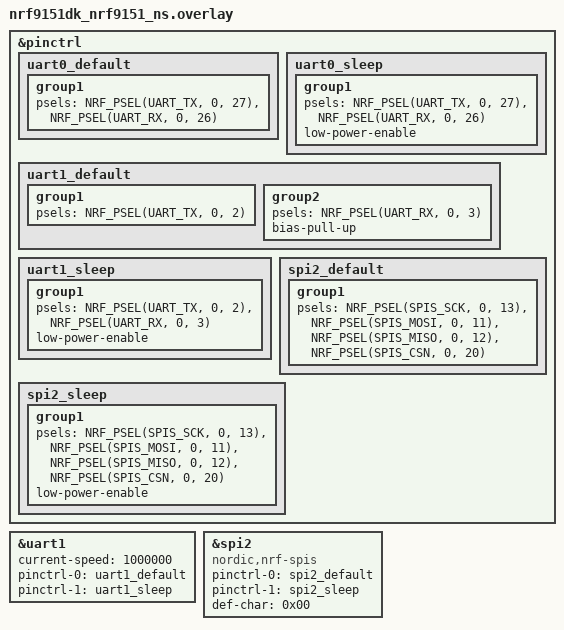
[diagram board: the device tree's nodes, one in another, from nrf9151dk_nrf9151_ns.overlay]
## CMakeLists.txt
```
#
# Copyright (c) 2025 Nordic Semiconductor ASA
#
# SPDX-License-Identifier: LicenseRef-Nordic-5-Clause
#

cmake_minimum_required(VERSION 3.20.0)

find_package(Zephyr REQUIRED HINTS $ENV{ZEPHYR_BASE})
project(hello_dect)

target_sources(app PRIVATE
    src/main.c
    src/uart.c
    src/sync.c
    src/dect_net.c
)

if(NOT CONFIG_DECT_RELAY_PT AND NOT CONFIG_DECT_RELAY_FT)
    target_sources(app PRIVATE src/spi.c)
endif()
```

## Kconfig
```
#
# Copyright (c) 2025 Nordic Semiconductor ASA
#
# SPDX-License-Identifier: LicenseRef-Nordic-5-Clause
#

source "Kconfig.zephyr"

menu "Hello DECT sample configuration"

config HELLO_DECT_MAC_DEMO_INTERVAL
	int "Demo message interval in seconds"
	default 30
	help
	  Interval in seconds for sending demo messages when connected.

config DECT_TRANSMITTER_ID
	int "DECT NR+ Transmitter ID"
	default 38
	help
	  DECT NR+ Transmitter ID (long rd id). Range 0..65535

config DECT_RELAY_PT
	bool "DECT NR+ Relay PT"
	default n
	help
	  Enable DECT NR+ Relay PT functionality. If enabled, the device will act as a relay for DECT NR+ messages.

config DECT_RELAY_FT
	bool "DECT NR+ Relay FT"
	default n
	help
	  Enable DECT NR+ Relay FT functionality. If enabled, the device will act as a relay for DECT NR+ messages.

config DECT_EDGE_PT
	bool "DECT NR+ PT Edge"
	default n
	help
	  Enable DECT NR+ Edge PT functionality.

config SPI
	depends on !DECT_RELAY_PT && !DECT_RELAY_FT


module = HELLO_DECT_MAC
module-str = Log level for Hello DECT sample application
source "${ZEPHYR_BASE}/subsys/logging/Kconfig.template.log_config"



endmenu
```

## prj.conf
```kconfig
# Modem library
CONFIG_NRF_MODEM_LIB=y
CONFIG_NRF_MODEM_LINK_BINARY_DECT=y
CONFIG_NRF_MODEM_LIB_ON_FAULT_APPLICATION_SPECIFIC=y

# DECT NR+ driver configuration
CONFIG_DECT=y
CONFIG_DECT_MDM=y
CONFIG_DECT_MDM_DRIVER_NRF=y

# DECT NR+ network ID for both devices
CONFIG_DECT_DEFAULT_NW_ID=0x12345678

# Networking
CONFIG_NETWORKING=y
CONFIG_NET_NATIVE=y
CONFIG_NET_IPV4=n
CONFIG_NET_IPV6=y
CONFIG_NRF_MODEM_LIB_SHMEM_TX_SIZE=16384

# Network management
CONFIG_NET_MGMT=y
CONFIG_NET_MGMT_EVENT=y
CONFIG_NET_MGMT_EVENT_INFO=y
CONFIG_NET_MGMT_EVENT_INFO_DEFAULT_DATA_SIZE=208

# DECT NR+ L2 and connection manager
CONFIG_NET_L2_DECT_MGMT=y
CONFIG_NET_CONNECTION_MANAGER=y
CONFIG_NET_CONNECTION_MANAGER_MONITOR_STACK_SIZE=2048
CONFIG_NET_L2_DECT_CONN_MGR_AUTO_CONNECT=n
CONFIG_NET_L2_DECT_CONN_MGR_CONNECTION_PERSISTENCE=y

# Basic networking components
CONFIG_NET_SOCKETS=y
CONFIG_NET_SOCKETS_PACKET=y
CONFIG_NET_SOCKETS_OFFLOAD=n
CONFIG_POSIX_API=y
CONFIG_NET_IF_MAX_IPV6_COUNT=2
CONFIG_NET_INTERFACE_NAME=y

# Network buffers
CONFIG_NET_BUF=y
CONFIG_NET_BUF_DATA_SIZE=1280
CONFIG_NET_PKT_RX_COUNT=8
CONFIG_NET_BUF_RX_COUNT=8
CONFIG_NET_PKT_TX_COUNT=4
CONFIG_NET_BUF_TX_COUNT=4

# IPv6 neighbor tables, ND itself disabled in net iface
CONFIG_NET_IPV6_NBR_CACHE=y
CONFIG_NET_IPV6_ND=y

# Disable antenna config (not supported by DECT modem)
CONFIG_MODEM_ANTENNA=n
CONFIG_MODEM_ANTENNA_AT_COEX0=""

# Basic kernel and system settings
CONFIG_MAIN_STACK_SIZE=8192
CONFIG_SYSTEM_WORKQUEUE_STACK_SIZE=4096

# DECT NR+ specific settings
CONFIG_DECT_TRANSMITTER_ID=9876
CONFIG_NET_MGMT_EVENT_STACK_SIZE=2048
CONFIG_NET_MGMT_EVENT_QUEUE_SIZE=10
CONFIG_NET_MGMT_EVENT_QUEUE_TIMEOUT=5000

# Enable DK library for LED/button support
CONFIG_DK_LIBRARY=y

# Settings storage
CONFIG_FLASH=y
CONFIG_FLASH_MAP=y
CONFIG_MPU_ALLOW_FLASH_WRITE=y
CONFIG_NVS=y
CONFIG_SETTINGS=y
CONFIG_SETTINGS_NVS=y

# Additional network socket configurations
CONFIG_NET_CONTEXT_SNDTIMEO=y
CONFIG_NET_CONTEXT_RCVTIMEO=y
CONFIG_NET_RX_STACK_SIZE=4096

# Hostname configuration
CONFIG_NET_HOSTNAME_ENABLE=y
CONFIG_NET_HOSTNAME="dect-nr+-device"
CONFIG_NET_HOSTNAME_DYNAMIC=y
CONFIG_NET_HOSTNAME_UNIQUE=n

# Need bigger stack for mDNS
CONFIG_NET_SOCKETS_SERVICE_STACK_SIZE=4096
CONFIG_NRF_MODEM_LIB_SHMEM_RX_SIZE=8192
# Enable logging
CONFIG_LOG=y
CONFIG_NET_LOG=y
CONFIG_PRINTK=y

# Debugging options
CONFIG_ASSERT=y
CONFIG_ASSERT_VERBOSE=y

# Halt application, e.g. on assertion failure
CONFIG_RESET_ON_FATAL_ERROR=n

# SPI
CONFIG_SPI=y
CONFIG_SPI_SLAVE=y

CONFIG_TFM_LOG_LEVEL_SILENCE=y

# UART (image data shares UART0/VCOM0 with log output)
CONFIG_SERIAL=y
CONFIG_UART_ASYNC_API=y

# Use deferred logging so log output does not interleave with binary data
CONFIG_LOG_MODE_DEFERRED=y
```

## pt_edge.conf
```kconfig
CONFIG_DECT_EDGE_PT=y
CONFIG_SPI=y
CONFIG_SPI_SLAVE=y
```

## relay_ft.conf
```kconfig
CONFIG_DECT_RELAY_FT=y
CONFIG_SPI=n
CONFIG_SPI_SLAVE=n
```

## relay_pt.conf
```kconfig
CONFIG_DECT_RELAY_PT=y
CONFIG_RING_BUFFER=y
CONFIG_RING_BUFFER_LARGE=y
CONFIG_SPI=n
CONFIG_SPI_SLAVE=n
```

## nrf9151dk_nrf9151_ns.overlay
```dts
&pinctrl {

    uart0_default: uart0_default {
        group1 {
            psels = <NRF_PSEL(UART_TX, 0, 27)>,
                    <NRF_PSEL(UART_RX, 0, 26)>;
        };
    };

    uart0_sleep: uart0_sleep {
        group1 {
            psels = <NRF_PSEL(UART_TX, 0, 27)>,
                    <NRF_PSEL(UART_RX, 0, 26)>;
            low-power-enable;
        };
    };

    uart1_default: uart1_default {
    group1 {
        psels = <NRF_PSEL(UART_TX, 0, 2)>;
    };
    group2 {
        psels = <NRF_PSEL(UART_RX, 0, 3)>;
        bias-pull-up;  /* RX needs pull-up, separate group */
    };
    };
    uart1_sleep: uart1_sleep {
        group1 {
            psels = <NRF_PSEL(UART_TX, 0, 2)>,
                    <NRF_PSEL(UART_RX, 0, 3)>;
            low-power-enable;
        };
    };

    spi2_default: spi2_default {
        group1 {
            psels = <NRF_PSEL(SPIS_SCK, 0, 13)>,
                    <NRF_PSEL(SPIS_MOSI, 0, 11)>,
                    <NRF_PSEL(SPIS_MISO, 0, 12)>,
                    <NRF_PSEL(SPIS_CSN, 0, 20)>;
        };
    };

    spi2_sleep: spi2_sleep {
        group1 {
            psels = <NRF_PSEL(SPIS_SCK, 0, 13)>,
                    <NRF_PSEL(SPIS_MOSI, 0, 11)>,
                    <NRF_PSEL(SPIS_MISO, 0, 12)>,
                    <NRF_PSEL(SPIS_CSN, 0, 20)>;
            low-power-enable;
        };
    };

};

&uart1 {
    status = "okay";
    current-speed = <1000000>;
    pinctrl-0 = <&uart1_default>;
    pinctrl-1 = <&uart1_sleep>;
    pinctrl-names = "default", "sleep";
};

&spi2 {
    compatible = "nordic,nrf-spis";
    status = "okay";
    pinctrl-0 = <&spi2_default>;
    pinctrl-1 = <&spi2_sleep>;
    pinctrl-names = "default", "sleep";
    def-char = <0x00>;
};
```

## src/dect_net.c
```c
#include "dect_net.h"

#include <zephyr/kernel.h>
#include <zephyr/logging/log.h>
#include <zephyr/net/net_mgmt.h>
#include <zephyr/net/net_ip.h>
#include <zephyr/posix/arpa/inet.h>

#include <net/dect/dect_net_l2_mgmt.h>
#include <net/dect/dect_net_l2.h>
#include <net/dect/dect_utils.h>

#include "uart.h"   /* ROUTING_MAX_HOPS */

LOG_MODULE_REGISTER(dect_net, LOG_LEVEL_INF);

#define RSSI_CACHE_SIZE ROUTING_MAX_HOPS

static struct net_if   *dect_iface;
static struct in6_addr  mesh_prefix;
static uint32_t         current_long_rd_id;
static uint32_t         best_long_rd_id;
static uint8_t          best_route_cost;

static struct {
    uint32_t long_rd_id;
    int8_t   rssi;
} rssi_cache[RSSI_CACHE_SIZE];

/* ── Internal helpers ── */

static bool create_ipv6_internal(struct in6_addr *addr, uint32_t long_rd_id)
{
    bool ok = dect_utils_lib_net_ipv6_addr_create_from_sink_and_long_rd_id(
        mesh_prefix, DECT_SINK_LONG_RD_ID, long_rd_id, addr);
    if (!ok) LOG_ERR("Failed to create IPv6 address for 0x%08x", long_rd_id);
    return ok;
}

static void create_and_set_device_ipv6(void)
{
    net_addr_pton(AF_INET6, MESH_PREFIX_STR, &mesh_prefix);

    struct in6_addr global_addr;
    if (!create_ipv6_internal(&global_addr, current_long_rd_id)) return;

    net_if_ipv6_addr_add(dect_iface, &global_addr, NET_ADDR_MANUAL, 0);

    char addr_str[NET_IPV6_ADDR_LEN];
    net_addr_ntop(AF_INET6, &global_addr, addr_str, sizeof(addr_str));
    LOG_INF("Adding global IPv6: %s", addr_str);
}

/* ── Public API ── */

void dect_net_init(struct net_if *iface)
{
    dect_iface      = iface;
    best_long_rd_id = 0;
    best_route_cost = 0xFF;
}

void dect_net_write_ft_settings(void)
{
    struct dect_settings s = {0};
    int ret = net_mgmt(NET_REQUEST_DECT_SETTINGS_READ, dect_iface, &s, sizeof(s));
    if (ret) {
        LOG_ERR("Failed to read settings: %d", ret);
        return;
    }

    s.device_type = DECT_DEVICE_TYPE_FT;
#if IS_ENABLED(CONFIG_DECT_RELAY_FT)
    s.identities.transmitter_long_rd_id = DECT_FT_LONG_RD_ID;
#else
    s.identities.transmitter_long_rd_id = DECT_SINK_LONG_RD_ID;
#endif

    // Disable auto-start
    s.auto_start.activate = false;

    s.nw_beacon.channel       = 1657;
    s.nw_beacon.beacon_period = DECT_NW_BEACON_PERIOD_1000MS;
    s.cmd_params.write_scope_bitmap =
        DECT_SETTINGS_WRITE_SCOPE_AUTO_START  |
        DECT_SETTINGS_WRITE_SCOPE_DEVICE_TYPE |
        DECT_SETTINGS_WRITE_SCOPE_IDENTITIES  |
        DECT_SETTINGS_WRITE_SCOPE_NW_BEACON;

    ret = net_mgmt(NET_REQUEST_DECT_SETTINGS_WRITE, dect_iface, &s, sizeof(s));
    if (ret) {
        LOG_ERR("Failed to write settings: %d", ret);
        return;
    }

    current_long_rd_id = s.identities.transmitter_long_rd_id;
    create_and_set_device_ipv6();
    LOG_INF("FT settings written (long_rd_id=0x%08x)", current_long_rd_id);
}

void dect_net_write_pt_settings(void)
{
    struct dect_settings s = {0};
    int ret = net_mgmt(NET_REQUEST_DECT_SETTINGS_READ, dect_iface, &s, sizeof(s));
    if (ret) {
        LOG_ERR("Failed to read settings: %d", ret);
        return; 
    }

    s.device_type = DECT_DEVICE_TYPE_PT;
#if IS_ENABLED(CONFIG_DECT_RELAY_PT)
    s.identities.transmitter_long_rd_id = DECT_PT_LONG_RD_ID;
#else
    s.identities.transmitter_long_rd_id = DECT_EDGE_PT_LONG_RD_ID;
#endif

    // Disable auto-start
    s.auto_start.activate = false;

    s.cmd_params.write_scope_bitmap =
        DECT_SETTINGS_WRITE_SCOPE_AUTO_START    |
        DECT_SETTINGS_WRITE_SCOPE_DEVICE_TYPE   |
        DECT_SETTINGS_WRITE_SCOPE_IDENTITIES;

    ret = net_mgmt(NET_REQUEST_DECT_SETTINGS_WRITE, dect_iface, &s, sizeof(s));
    if (ret) {
        LOG_ERR("Failed to write settings: %d", ret);
        return;
    }

    current_long_rd_id = s.identities.transmitter_long_rd_id;
    create_and_set_device_ipv6();
    LOG_INF("PT settings written (long_rd_id=0x%08x)", current_long_rd_id);
}

void dect_net_start_beacon(void)
{
    struct dect_nw_beacon_start_req_params p = {
        .channel = 1657,
        .additional_ch_count = 0,
    };
    int ret = net_mgmt(NET_REQUEST_DECT_NW_BEACON_START, dect_iface, &p, sizeof(p));
    if (ret) LOG_ERR("Beacon start failed: %d", ret);
}

void dect_net_start_scan(void)
{
    best_long_rd_id = 0;
    best_route_cost = 0xFF;

    struct dect_scan_params p = {
        .band = 1,
        .channel_count = 0,
        .channel_scan_time_ms = 1200,
    };
    int ret = net_mgmt(NET_REQUEST_DECT_SCAN, dect_iface, &p, sizeof(p)); // Callback to NET_EVENT_DECT_SCAN_RESULT and NET_EVENT_DECT_SCAN_DONE
    if (ret) LOG_ERR("Scan start failed: %d", ret);
}

void dect_net_consider_ft(uint32_t long_rd_id, uint8_t route_cost)
{
    if (route_cost < best_route_cost) {
        best_route_cost = route_cost;
        best_long_rd_id = long_rd_id;
        LOG_INF("New best FT: 0x%08x (cost=%d)", best_long_rd_id, best_route_cost);
    }
}

bool dect_net_has_best_ft(void)
{
    return best_long_rd_id != 0;
}

void dect_net_join_best(void)
{
    struct dect_settings s = {0};
    int ret = net_mgmt(NET_REQUEST_DECT_SETTINGS_READ, dect_iface, &s, sizeof(s));
    if (ret) { LOG_ERR("Failed to read settings: %d", ret); return; }

    s.network_join.target_ft_long_rd_id = best_long_rd_id;
    s.cmd_params.write_scope_bitmap |= DECT_SETTINGS_WRITE_SCOPE_NETWORK_JOIN;

    ret = net_mgmt(NET_REQUEST_DECT_SETTINGS_WRITE, dect_iface, &s, sizeof(s));
    if (ret) { LOG_ERR("Failed to write join settings: %d", ret); return; }

    ret = net_mgmt(NET_REQUEST_DECT_NETWORK_JOIN, dect_iface, NULL, 0); // Callback to NET_EVENT_DECT_NETWORK_STATUS->Joined
    if (ret) LOG_ERR("Network join failed: %d", ret);
    else     LOG_INF("Joining FT 0x%08x", best_long_rd_id);
}

uint32_t dect_net_get_current_long_rd_id(void)
{
    return current_long_rd_id;
}

const struct in6_addr *dect_net_get_mesh_prefix(void)
{
    return &mesh_prefix;
}

uint32_t dect_net_get_parent_long_rd_id(void)
{
    struct dect_status_info info = {0};
    int ret = net_mgmt(NET_REQUEST_DECT_STATUS_INFO_GET, dect_iface, &info, sizeof(info));
    if (ret) { LOG_ERR("Failed to get status info: %d", ret); return 0; }
    if (info.parent_count == 0) return 0;
    return info.parent_associations->long_rd_id;
}

bool dect_net_create_ipv6(struct in6_addr *addr, uint32_t long_rd_id)
{
    return create_ipv6_internal(addr, long_rd_id);
}

void dect_net_update_rssi(uint32_t long_rd_id, int8_t rssi)
{
    for (int i = 0; i < RSSI_CACHE_SIZE; i++) {
        if (rssi_cache[i].long_rd_id == long_rd_id || rssi_cache[i].long_rd_id == 0) {
            rssi_cache[i].long_rd_id = long_rd_id;
            rssi_cache[i].rssi       = rssi;
            return;
        }
    }
    /* Cache full - overwrite slot 0 */
    rssi_cache[0].long_rd_id = long_rd_id;
    rssi_cache[0].rssi       = rssi;
}

int8_t dect_net_get_rx_rssi(struct sockaddr_in6 *src_addr)
{
    uint32_t long_rd_id = dect_utils_lib_long_rd_id_from_ipv6_addr(&src_addr->sin6_addr);
    if (long_rd_id == 0) return 0;

    struct dect_neighbor_info_req_params p = { .long_rd_id = long_rd_id };
    int ret = net_mgmt(NET_REQUEST_DECT_NEIGHBOR_INFO, dect_iface, &p, sizeof(p));
    if (ret) LOG_WRN("Neighbor info request failed: %d", ret);

    for (int i = 0; i < RSSI_CACHE_SIZE; i++) {
        if (rssi_cache[i].long_rd_id == long_rd_id) return rssi_cache[i].rssi;
    }
    return 0;
}
```

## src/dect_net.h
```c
#ifndef DECT_NET_H
#define DECT_NET_H

#include <zephyr/net/net_if.h>
#include <zephyr/net/net_ip.h>
#include <zephyr/posix/sys/socket.h>
#include <stdint.h>
#include <stdbool.h>

/* Device identities - single source of truth for the whole project */
#define DECT_EDGE_PT_LONG_RD_ID     0xAAAAAAAAU

//#define DECT_FT_LONG_RD_ID          0xBBBBBBBBU
//#define DECT_PT_LONG_RD_ID          0xCCCCCCCCU

#define DECT_FT_LONG_RD_ID          0xDDDDDDDDU
#define DECT_PT_LONG_RD_ID          0xEEEEEEEEU

#define DECT_SINK_LONG_RD_ID        0x67FFFFFFU
#define MESH_PREFIX_STR           "fd12:3456:789a"

/* Must be called before any other dect_net function */
void dect_net_init(struct net_if *iface);

/* Settings */
void dect_net_write_ft_settings(void);
void dect_net_write_pt_settings(void);

/* Network operations */
void dect_net_start_beacon(void);
void dect_net_start_scan(void);
void dect_net_consider_ft(uint32_t long_rd_id, uint8_t route_cost);
bool dect_net_has_best_ft(void);
void dect_net_join_best(void);

/* Queries */
uint32_t             dect_net_get_current_long_rd_id(void);
const struct in6_addr *dect_net_get_mesh_prefix(void);
uint32_t             dect_net_get_parent_long_rd_id(void);
bool                 dect_net_create_ipv6(struct in6_addr *addr, uint32_t long_rd_id);

/* RSSI - update called from NET_EVENT_DECT_NEIGHBOR_INFO handler */
void   dect_net_update_rssi(uint32_t long_rd_id, int8_t rssi);
int8_t dect_net_get_rx_rssi(struct sockaddr_in6 *src_addr);

#endif /* DECT_NET_H */
```

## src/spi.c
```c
#include <zephyr/kernel.h>
#include <zephyr/device.h>
#include <zephyr/drivers/spi.h>
#include <zephyr/logging/log.h>
#include "spi.h"

LOG_MODULE_REGISTER(spi_slave, LOG_LEVEL_INF);

#define READY_PIN_NODE DT_NODELABEL(gpio0)
#define READY_PIN 6

static const struct device *gpio_dev;

#define SPI_NODE DT_NODELABEL(spi2)
#define TX_BUFFER_SIZE 1024
#define CHUNK_SIZE 4096
#define MAX_IMAGE_SIZE 16384

K_THREAD_STACK_DEFINE(spi_slave_stack, 12288);
static struct k_thread spi_slave_thread_data;
static k_tid_t spi_slave_thread_id;

static uint8_t tx_buffer[TX_BUFFER_SIZE];
static uint8_t rx_buffer[CHUNK_SIZE];
static uint8_t image_buffer[MAX_IMAGE_SIZE];

static size_t total_received = 0;
static size_t image_size = 0;
static bool new_image_available = false;
static bool receiving_image = false;
K_MUTEX_DEFINE(image_mutex);

static struct spi_config spi_cfg = {
    .frequency = 8000000,
    .operation = SPI_OP_MODE_SLAVE |
                 SPI_TRANSFER_MSB |
                 SPI_WORD_SET(8) |
                 SPI_MODE_CPOL |
                 SPI_MODE_CPHA,
    .slave = 0,
    .cs = NULL};

static struct spi_buf tx_buf = {
    .buf = tx_buffer,
    .len = TX_BUFFER_SIZE};

static struct spi_buf_set tx_buf_set = {
    .buffers = &tx_buf,
    .count = 1};

static struct spi_buf rx_buf = {
    .buf = rx_buffer,
    .len = CHUNK_SIZE};

static struct spi_buf_set rx_buf_set = {
    .buffers = &rx_buf,
    .count = 1};

static bool find_jpeg_end(uint8_t *buffer, size_t len, size_t *end_pos)
{
    bool found = false;

    if (len < 2) return false;

    for (size_t i = 0; i < len - 1; i++)
    {
        if (buffer[i] == 0xFF && buffer[i + 1] == 0xD9)
        {
            *end_pos = i + 2;
            found = true;
        }
    }
    return found;
}

int spi_slave_init(void)
{
    const struct device *spi_dev;

    LOG_INF("Initializing SPI slave...");
    spi_dev = DEVICE_DT_GET(SPI_NODE);

    if (spi_dev == NULL)
    {
        LOG_ERR("Device pointer is NULL!");
        return -ENODEV;
    }

    if (!device_is_ready(spi_dev))
    {
        LOG_ERR("SPI device not ready");
        return -ENODEV;
    }
    gpio_dev = DEVICE_DT_GET(READY_PIN_NODE);
    if (!device_is_ready(gpio_dev))
    {
        LOG_ERR("GPIO device not ready");
        return -ENODEV;
    }

    gpio_pin_configure(gpio_dev, READY_PIN, GPIO_OUTPUT_ACTIVE);
    gpio_pin_set(gpio_dev, READY_PIN, 0);  /* Not ready until thread arms */

    LOG_INF("Ready pin (P0.06) initialized");
    LOG_INF("SPI slave initialized: %s", spi_dev->name);
    return 0;
}

void spi_slave_receive_thread(void *p1, void *p2, void *p3)
{
    const struct device *spi_dev;
    int ret;
    size_t eoi_pos;
    uint8_t prev_last_byte = 0;

    ARG_UNUSED(p1);
    ARG_UNUSED(p2);
    ARG_UNUSED(p3);

    LOG_INF("SPI slave thread starting...");

    spi_dev = DEVICE_DT_GET(SPI_NODE);
    if (!device_is_ready(spi_dev))
    {
        LOG_ERR("SPI device not ready");
        return;
    }

    LOG_INF("SPI slave ready, waiting for master...");

    while (1)
    {
        /* If the previous image has not been consumed yet, keep ready LOW and
         * wait here. The SPI thread owns the ready pin - it will raise it once
         * it re-arms spi_transceive. */
        {
            bool pending;
            do {
                k_mutex_lock(&image_mutex, K_FOREVER);
                pending = new_image_available;
                k_mutex_unlock(&image_mutex);
                if (pending) k_sleep(K_MSEC(10));
            } while (pending);
        }

        /* Arm the slave for the next chunk.
         * Signal ready HIGH *before* calling spi_transceive. The Pi requires
         * at least ~100µs of Python/ioctl overhead after seeing HIGH before CS
         * is asserted, which is far longer than the ~5µs spi_transceive needs
         * to arm the SPIS hardware. The race window is negligible in practice. */
        rx_buf.len = CHUNK_SIZE;
        tx_buf.len = TX_BUFFER_SIZE;
        gpio_pin_set(gpio_dev, READY_PIN, 1);
        ret = spi_transceive(spi_dev, &spi_cfg, &tx_buf_set, &rx_buf_set);

        /* Signal LOW immediately - tells Pi "I'm processing, don't send yet".
         * Pi will wait for this LOW then the next HIGH before sending the
         * following chunk. */
        gpio_pin_set(gpio_dev, READY_PIN, 0);

        if (ret < 0)
        {
            LOG_ERR("SPI transceive failed: %d", ret);
            continue;
        }

        size_t bytes_received = rx_buf.len;
        if (bytes_received == 0)
            continue;

        /* Detect start of new image */
        if (rx_buffer[0] == 0xFF && rx_buffer[1] == 0xD8)
        {
            total_received = 0;
            receiving_image = true;
            prev_last_byte = 0;
            memset(image_buffer, 0, MAX_IMAGE_SIZE);
            LOG_INF("New image started");
        }

        if (!receiving_image)
            continue;

        if (total_received + bytes_received > MAX_IMAGE_SIZE)
        {
            LOG_ERR("Image too large, discarding (total=%zu)", total_received);
            receiving_image = false;
            total_received = 0;
            prev_last_byte = 0;
            continue;
        }

        memcpy(image_buffer + total_received, rx_buffer, bytes_received);
        total_received += bytes_received;

        bool eoi_found = false;

        if (prev_last_byte == 0xFF && rx_buffer[0] == 0xD9)
        {
            eoi_pos = 1;
            eoi_found = true;
            LOG_INF("EOI detected across chunk boundary");
        }
        else if (find_jpeg_end(rx_buffer, bytes_received, &eoi_pos))
        {
            eoi_found = true;
        }

        if (eoi_found)
        {
            size_t actual_size = (total_received - bytes_received) + eoi_pos;
            receiving_image = false;
            prev_last_byte = 0;

            k_mutex_lock(&image_mutex, K_FOREVER);
            image_size = actual_size;
            new_image_available = true;
            k_mutex_unlock(&image_mutex);

            LOG_INF("Image complete: %zu bytes", actual_size);
            /* Ready pin stays LOW. Loop restarts and waits at the top until
             * the app consumes the image, then re-arms and raises ready. */
        }
        else
        {
            prev_last_byte = rx_buffer[bytes_received - 1];
            /* Loop back immediately - ready will be raised at the top of the
             * next iteration once spi_transceive is about to be called. */
        }
    }
}

uint8_t *spi_slave_get_image_buffer(void)
{
    return image_buffer;
}

size_t spi_slave_get_image_size(void)
{
    size_t size;
    k_mutex_lock(&image_mutex, K_FOREVER);
    size = image_size;
    k_mutex_unlock(&image_mutex);
    return size;
}

bool spi_slave_is_new_image_available(void)
{
    bool available;
    k_mutex_lock(&image_mutex, K_FOREVER);
    available = new_image_available;
    k_mutex_unlock(&image_mutex);
    return available;
}

void spi_slave_clear_image_flag(void)
{
    k_mutex_lock(&image_mutex, K_FOREVER);
    new_image_available = false;
    k_mutex_unlock(&image_mutex);
    /* Do NOT touch the ready pin here. The SPI thread owns it and will raise
     * it on its next iteration once it has armed spi_transceive. */
    LOG_INF("Image consumed, SPI thread will re-arm");
}

int spi_slave_start_thread(void)
{
    spi_slave_thread_id = k_thread_create(&spi_slave_thread_data,
                                          spi_slave_stack,
                                          K_THREAD_STACK_SIZEOF(spi_slave_stack),
                                          spi_slave_receive_thread,
                                          NULL, NULL, NULL,
                                          7, 0, K_NO_WAIT);

    if (spi_slave_thread_id == NULL)
    {
        LOG_ERR("Failed to create SPI slave thread");
        return -1;
    }

    k_thread_name_set(spi_slave_thread_id, "spi_slave");
    LOG_INF("SPI slave thread started");
    return 0;
}
```

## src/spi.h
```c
#ifndef SPI_SLAVE_H
#define SPI_SLAVE_H

#include <stdint.h>
#include <stddef.h>
#include <stdbool.h>


int spi_slave_init(void);
void spi_slave_receive_thread(void *p1, void *p2, void *p3);
uint8_t* spi_slave_get_image_buffer(void);
size_t spi_slave_get_image_size(void);
bool spi_slave_is_new_image_available(void);
void spi_slave_clear_image_flag(void);
int spi_slave_start_thread(void);

#endif // SPI_SLAVE_H
```

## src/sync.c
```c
#include "sync.h"

#include <zephyr/kernel.h>
#include <zephyr/logging/log.h>
#include <zephyr/net/socket.h>
#include <zephyr/posix/arpa/inet.h>

#include <net/dect/dect_utils.h>

LOG_MODULE_REGISTER(sync, LOG_LEVEL_INF);

#define SYNC_MAGIC_SIGNATURE    0xFEFDU     // The G.O.A.T
#define SYNC_T_SIZE             4
#define SOCKET_SYNC_RX_TIMEOUT_SEC  10
#define SYNC_MAX_RX_RETRIES     5

struct sync_data {
    uint32_t magic_signature;
    uint32_t T[SYNC_T_SIZE];
};

/* Module state set by sync_init() */
static struct net_if   *sync_iface;
static struct in6_addr  sync_mesh_prefix;
static uint32_t         sync_sink_long_rd_id;

static int sync_socket = -1;

/* ── Internal helpers ── */

static bool make_peer_addr(struct sockaddr_in6 *addr, uint32_t long_rd_id)
{
    bool ok = dect_utils_lib_net_ipv6_addr_create_from_sink_and_long_rd_id(
        sync_mesh_prefix, sync_sink_long_rd_id, long_rd_id, &addr->sin6_addr);
    if (!ok) {
        LOG_ERR("Failed to construct IPv6 address for 0x%08x", long_rd_id);
    }
    return ok;
}

static int recv_sync_from_peer(struct sync_data *out, uint32_t *rx_long_rd_id_out,
                               uint32_t *timestamp_out, struct sockaddr_in6 *src_addr_out)
{
    struct sockaddr_in6 src_addr;
    socklen_t addr_len = sizeof(src_addr);
    char addr_str[NET_IPV6_ADDR_LEN];

    int ret = recvfrom(sync_socket, out, sizeof(*out), 0,
                       (struct sockaddr *)&src_addr, &addr_len);
    if (ret < 0) return -errno;

    *timestamp_out = k_uptime_get_32();

    if (out->magic_signature != SYNC_MAGIC_SIGNATURE) {
        LOG_WRN("SYNC magic mismatch (got 0x%08x)", out->magic_signature);
        return -EBADMSG;
    }

    net_addr_ntop(AF_INET6, &src_addr.sin6_addr, addr_str, sizeof(addr_str));
    *rx_long_rd_id_out = dect_utils_lib_long_rd_id_from_ipv6_addr(&src_addr.sin6_addr);
    LOG_INF("SYNC RX: %d bytes from %s (0x%08x)", ret, addr_str, *rx_long_rd_id_out);

    if (src_addr_out) *src_addr_out = src_addr;
    return 0;
}

/* ── Public API ── */

void sync_init(struct net_if *iface, const struct in6_addr *mesh_prefix,
               uint32_t sink_long_rd_id)
{
    sync_iface          = iface;
    sync_mesh_prefix    = *mesh_prefix;
    sync_sink_long_rd_id = sink_long_rd_id;
}

int sync_open_socket(void)
{
    sync_socket = socket(AF_INET6, SOCK_DGRAM, IPPROTO_UDP);
    if (sync_socket < 0) {
        LOG_ERR("Failed to create SYNC socket: %d", errno);
        sync_socket = -1;
        return -errno;
    }

    struct timeval timeout = { .tv_sec = SOCKET_SYNC_RX_TIMEOUT_SEC };
    int dect_iface_idx = net_if_get_by_iface(sync_iface);
    int reuse = 1;

    setsockopt(sync_socket, SOL_SOCKET, SO_RCVTIMEO, &timeout, sizeof(timeout));
    setsockopt(sync_socket, SOL_SOCKET, SO_BINDTODEVICE,
               &dect_iface_idx, sizeof(dect_iface_idx));
    setsockopt(sync_socket, SOL_SOCKET, SO_REUSEADDR, &reuse, sizeof(reuse));

    struct sockaddr_in6 rx_addr = {
        .sin6_family = AF_INET6,
        .sin6_port   = htons(SYNC_PORT),
        .sin6_addr   = in6addr_any,
    };

    int ret = bind(sync_socket, (struct sockaddr *)&rx_addr, sizeof(rx_addr));
    if (ret < 0) {
        LOG_ERR("Failed to bind SYNC socket: %d", errno);
        close(sync_socket);
        sync_socket = -1;
        return -errno;
    }

    LOG_INF("SYNC socket open");
    return 0;
}

void sync_close_socket(void)
{
    if (sync_socket >= 0) {
        close(sync_socket);
        sync_socket = -1;
    }
    LOG_INF("SYNC socket closed");
}

int sync_pt_operation(uint32_t parent_long_rd_id, int32_t *offset_out)
{
    if (sync_socket < 0) {
        LOG_WRN("SYNC socket not open");
        return -ENOTCONN;
    }

    struct sockaddr_in6 dst_addr = {
        .sin6_family = AF_INET6,
        .sin6_port   = htons(SYNC_PORT),
    };
    if (!make_peer_addr(&dst_addr, parent_long_rd_id)) {
        return -EINVAL;
    }

    for (int attempt = 0; attempt < SYNC_MAX_RX_RETRIES; attempt++) {
        /* Send T0 on every attempt so FT Relay gets it even if it wasn't ready */
        struct sync_data pkt = {
            .magic_signature = SYNC_MAGIC_SIGNATURE,
        };
        pkt.T[0] = k_uptime_get_32();

        int ret = sendto(sync_socket, &pkt, sizeof(pkt), 0,
                         (struct sockaddr *)&dst_addr, sizeof(dst_addr));
        if (ret < 0) {
            LOG_WRN("Failed to send SYNC packet: %d", errno);
            continue;
        }
        LOG_INF("SYNC T0 sent (attempt %d, T0=%u)", attempt + 1, pkt.T[0]);

        struct sync_data rx;
        uint32_t rx_long_rd_id;
        uint32_t T3;

        ret = recv_sync_from_peer(&rx, &rx_long_rd_id, &T3, NULL);
        if (ret == -EAGAIN) {
            LOG_WRN("SYNC RX timeout, retrying (%d/%d)", attempt + 1, SYNC_MAX_RX_RETRIES);
            continue;
        }
        if (ret < 0) {
            LOG_WRN("SYNC RX error: %d, retrying", ret);
            continue;
        }
        if (rx_long_rd_id != parent_long_rd_id) {
            LOG_WRN("SYNC RX from unexpected peer 0x%08x (want 0x%08x), retrying",
                    rx_long_rd_id, parent_long_rd_id);
            continue;
        }

        int32_t d1 = (int32_t)(rx.T[1] - pkt.T[0]);   /* T1 - T0 */
        int32_t d2 = (int32_t)(T3 - rx.T[2]);          /* T3 - T2 */
        *offset_out = (d1 - d2) / 2;
        LOG_INF("PTP: d1=%d d2=%d offset=%d", d1, d2, *offset_out);
                return 0;
    }

    LOG_WRN("SYNC PT: exhausted retries");
    return -ETIMEDOUT;
}
int sync_ft_operation(uint32_t child_long_rd_id)
{
    if (sync_socket < 0) {
        LOG_WRN("SYNC socket not open");
        return -ENOTCONN;
    }

    for (int attempt = 0; attempt < SYNC_MAX_RX_RETRIES; attempt++) {
        struct sync_data rx;
        uint32_t rx_long_rd_id;
        uint32_t T1;
        struct sockaddr_in6 reply_addr;

        int ret = recv_sync_from_peer(&rx, &rx_long_rd_id, &T1, &reply_addr);
        if (ret == -EAGAIN) {
            LOG_WRN("SYNC RX timeout, retrying (%d/%d)", attempt + 1, SYNC_MAX_RX_RETRIES);
            continue;
        }
        if (ret < 0) {
            LOG_WRN("SYNC RX error: %d, retrying", ret);
            continue;
        }
        if (rx_long_rd_id != child_long_rd_id) {
            LOG_WRN("SYNC RX from unexpected peer 0x%08x (want 0x%08x), retrying",
                    rx_long_rd_id, child_long_rd_id);
            continue;
        }

        reply_addr.sin6_port = htons(SYNC_PORT);

        struct sync_data reply = {
            .magic_signature = SYNC_MAGIC_SIGNATURE,
        };
        reply.T[0] = rx.T[0];
        reply.T[1] = T1;
        reply.T[2] = k_uptime_get_32();

        ret = sendto(sync_socket, &reply, sizeof(reply), 0,
                     (struct sockaddr *)&reply_addr, sizeof(reply_addr));
        if (ret < 0) {
            LOG_WRN("Failed to send SYNC reply: %d", errno);
            return -errno;
        }

        LOG_INF("SYNC reply sent (T0=%u T1=%u T2=%u)", reply.T[0], reply.T[1], reply.T[2]);
        return 0;
    }

    LOG_WRN("SYNC FT: exhausted retries");
    return -ETIMEDOUT;
}
```

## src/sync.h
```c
#ifndef SYNC_H
#define SYNC_H

#include <zephyr/net/net_if.h>
#include <zephyr/net/net_ip.h>
#include <stdint.h>

#define SYNC_PORT 12346

/*
 * sync_init - store the DECT interface, mesh prefix, and sink long RD ID
 * needed to construct IPv6 addresses for SYNC peers.
 *
 * Must be called before sync_open_socket or either operation.
 */
void sync_init(struct net_if *iface, const struct in6_addr *mesh_prefix,
               uint32_t sink_long_rd_id);

/* Open/close the dedicated SYNC UDP socket (driven by IF_UP / IF_DOWN). */
int  sync_open_socket(void);
void sync_close_socket(void);

/*
 * sync_pt_operation - PT side: send T0, receive T1/T2, compute clock offset.
 *
 * @param parent_long_rd_id  Long RD ID of the parent FT to synchronise with.
 * @param offset_out         Receives the computed PT-to-FT clock offset (ms).
 *
 * Returns 0 on success, negative on failure or timeout.
 */
int sync_pt_operation(uint32_t parent_long_rd_id, int32_t *offset_out);

/*
 * sync_ft_operation - FT side: receive T0 from child PT, echo T1/T2 back.
 *
 * @param child_long_rd_id  Long RD ID of the expected child PT.
 *
 * Returns 0 on success, negative on failure or timeout.
 */
int sync_ft_operation(uint32_t child_long_rd_id);

#endif /* SYNC_H */
```

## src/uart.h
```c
#ifndef UART_DATA_H
#define UART_DATA_H

#include <zephyr/kernel.h>
#include <stdint.h>

#define ROUTING_MAX_HOPS    8
#define MAX_PAYLOAD_SIZE    1024
#define CHUNK_POOL_COUNT    16

struct hop_delays {
    uint8_t  num_links;
    uint32_t devices_visited[ROUTING_MAX_HOPS];
    int32_t per_link_delay[ROUTING_MAX_HOPS];
    int8_t   per_link_rssi[ROUTING_MAX_HOPS];
};

struct data_packet {
    uint16_t packet_idx;
    uint16_t total_packets;
    uint32_t total_data_size;
    uint16_t seq_num;
    uint32_t timestamp_pt;
    int32_t  offset_pt_to_ft;
    struct hop_delays route_delays;
    uint16_t payload_len;
    uint8_t  payload[];
} __attribute__((packed));

/* Single source of truth - can never drift from the actual struct layout */
#define CHUNK_BUF_SIZE  (sizeof(struct data_packet) + MAX_PAYLOAD_SIZE)

struct rx_chunk {
    void    *fifo_reserved;
    uint16_t data_len;
    uint8_t  data[CHUNK_BUF_SIZE];
};

struct packet_metadata {
    uint32_t seq_num;
    uint32_t timestamp_pt;
    int32_t  offset_pt_to_ft;
    struct hop_delays route_delays;
};

int uart_data_init(void);
int uart_send_image(const uint8_t *data, uint32_t length, const struct packet_metadata *meta);
int uart_stream_begin(uint32_t total_length);
int uart_stream_chunk(const uint8_t *data, uint16_t len);
int uart_stream_end(const struct packet_metadata *meta);
int uart_rx_start(void);
int uart_tx_thread_start(void);
struct rx_chunk *uart_get_free_chunk(void);
void uart_return_free_chunk(struct rx_chunk *chunk);
void uart_queue_chunk(struct rx_chunk *chunk);
bool uart_is_ready(void);

typedef void (*uart_rx_frame_cb_t)(const uint8_t *data, uint32_t len,
                                    const struct packet_metadata *meta);
void uart_rx_set_frame_callback(uart_rx_frame_cb_t cb);

int uart_handshake_init(void);
int uart_handshake_send_id_timestamp(uint32_t long_rd_id);
int uart_handshake_receive_id_timestamp(uint32_t *long_rd_id, int32_t *offset, int timeout_sec);
void uart_rx_release_payload(void);
#endif
```
